VERSION "Tesla Model Y HW4 read-only perception and navigation subset"

NS_ :

BS_:

BU_: UI DAS APP

CM_ "Read-only Model Y HW4 visualization subset. Source: https://tcan.latency.is/?plat=ModelY, retrieved 2026-08-03. Counter and checksum fields are intentionally omitted.";

BO_ 568 UI_driverAssistMapData: 8 UI
 SG_ UI_mapSpeedLimitDependency : 0|3@1+ (1,0) [0|7] "" DAS
 SG_ UI_roadClass : 3|3@1+ (1,0) [0|7] "" DAS
 SG_ UI_inSuperchargerGeofence : 6|1@1+ (1,0) [0|1] "" DAS
 SG_ UI_mapSpeedUnits : 7|1@1+ (1,0) [0|1] "" DAS
 SG_ UI_mapSpeedLimit : 8|5@1+ (1,0) [0|31] "" DAS
 SG_ UI_mapSpeedLimitType : 13|3@1+ (1,0) [0|7] "" DAS
 SG_ UI_countryCode : 16|10@1+ (1,0) [0|1023] "" DAS
 SG_ UI_streetCount : 26|2@1+ (1,0) [0|3] "" DAS
 SG_ UI_gpsRoadMatch : 28|1@1+ (1,0) [0|1] "" DAS
 SG_ UI_navRouteActive : 29|1@1+ (1,0) [0|1] "" DAS
 SG_ UI_parallelAutoparkEnabled : 30|1@1+ (1,0) [0|1] "" DAS
 SG_ UI_perpendicularAutoparkEnabled : 31|1@1+ (1,0) [0|1] "" DAS
 SG_ UI_nextBranchDist : 32|5@1+ (10,0) [0|310] "m" DAS
 SG_ UI_controlledAccess : 37|1@1+ (1,0) [0|1] "" DAS
 SG_ UI_nextBranchLeftOffRamp : 38|1@1+ (1,0) [0|1] "" DAS
 SG_ UI_nextBranchRightOffRamp : 39|1@1+ (1,0) [0|1] "" DAS
 SG_ UI_rejectLeftLane : 40|1@1+ (1,0) [0|1] "" DAS
 SG_ UI_rejectRightLane : 41|1@1+ (1,0) [0|1] "" DAS
 SG_ UI_rejectHPP : 42|1@1+ (1,0) [0|1] "" DAS
 SG_ UI_rejectNav : 43|1@1+ (1,0) [0|1] "" DAS
 SG_ UI_rejectLeftFreeSpace : 44|1@1+ (1,0) [0|1] "" DAS
 SG_ UI_rejectRightFreeSpace : 45|1@1+ (1,0) [0|1] "" DAS
 SG_ UI_rejectAutosteer : 46|1@1+ (1,0) [0|1] "" DAS
 SG_ UI_rejectHandsOn : 47|1@1+ (1,0) [0|1] "" DAS
 SG_ UI_acceptBottsDots : 48|1@1+ (1,0) [0|1] "" DAS
 SG_ UI_autosteerRestricted : 49|1@1+ (1,0) [0|1] "" DAS
 SG_ UI_pmmEnabled : 50|1@1+ (1,0) [0|1] "" DAS
 SG_ UI_scaEnabled : 51|1@1+ (1,0) [0|1] "" DAS

BO_ 586 DAS_visualDebug: 8 DAS
 SG_ DAS_autosteerVehiclesUsage : 4|2@1+ (1,0) [0|3] "" UI
 SG_ DAS_autosteerHPPUsage : 6|2@1+ (1,0) [0|3] "" UI
 SG_ DAS_autosteerNavigationUsage : 8|2@1+ (1,0) [0|3] "" UI
 SG_ DAS_autosteerModelUsage : 10|2@1+ (1,0) [0|3] "" UI
 SG_ DAS_autosteerBottsDotsUsage : 12|2@1+ (1,0) [0|3] "" UI
 SG_ DAS_offsetSide : 14|2@1+ (1,0) [0|3] "" UI
 SG_ DAS_roadSurfaceType : 16|2@1+ (1,0) [0|3] "" UI
 SG_ DAS_autosteerHealthAnomalyLevel : 18|3@1+ (1,0) [0|7] "" UI
 SG_ DAS_autosteerHealthState : 21|3@1+ (1,0) [0|7] "" UI
 SG_ DAS_lastLinePreferenceReason : 24|4@1+ (1,0) [0|15] "" UI
 SG_ DAS_plannerState : 28|4@1+ (1,0) [0|15] "" UI
 SG_ DAS_lastAutosteerAbortReason : 32|6@1+ (1,0) [0|63] "" UI
 SG_ DAS_devAppInterfaceEnabled : 38|1@1+ (1,0) [0|1] "" UI
 SG_ DAS_navAvailable : 39|1@1+ (1,0) [0|1] "" UI
 SG_ DAS_navDistance : 40|8@1+ (100,0) [0|25500] "m" UI
 SG_ DAS_accSmartSpeedActive : 48|1@1+ (1,0) [0|1] "" UI
 SG_ DAS_accSmartSpeedState : 49|3@1+ (1,0) [0|7] "" UI
 SG_ DAS_ulcInProgress : 52|1@1+ (1,0) [0|1] "" UI
 SG_ DAS_trafficAwareSetSpeedInUse : 53|1@1+ (1,0) [0|1] "" UI
 SG_ DAS_isaSystemState : 54|2@1+ (1,0) [0|3] "" UI
 SG_ DAS_behaviorType : 56|2@1+ (1,0) [0|3] "" UI
 SG_ DAS_ulcType : 58|2@1+ (1,0) [0|3] "" UI
 SG_ DAS_rearVehDetectedThisCycle : 60|1@1+ (1,0) [0|1] "" UI
 SG_ DAS_rearLeftVehDetectedCurrent : 61|1@1+ (1,0) [0|1] "" UI
 SG_ DAS_rearRightVehDetectedTrip : 62|1@1+ (1,0) [0|1] "" UI
 SG_ DAS_rearLeftVehDetectedTrip : 63|1@1+ (1,0) [0|1] "" UI

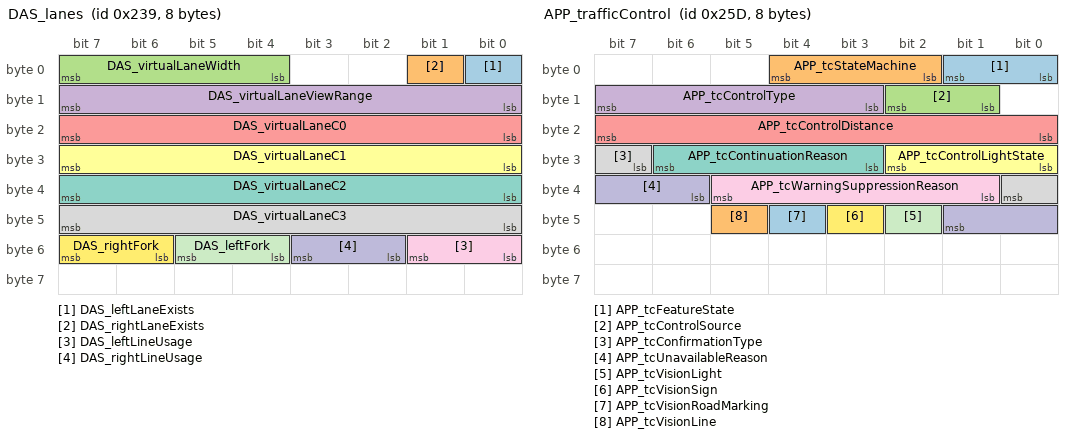
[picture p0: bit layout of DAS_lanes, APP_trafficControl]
BO_ 569 DAS_lanes: 8 DAS
 SG_ DAS_leftLaneExists : 0|1@1+ (1,0) [0|1] "" UI
 SG_ DAS_rightLaneExists : 1|1@1+ (1,0) [0|1] "" UI
 SG_ DAS_virtualLaneWidth : 4|4@1+ (0.3125,2) [2|6.6875] "m" UI
 SG_ DAS_virtualLaneViewRange : 8|8@1+ (1,0) [0|255] "m" UI
 SG_ DAS_virtualLaneC0 : 16|8@1+ (0.035,-3.5) [-3.5|5.425] "m" UI
 SG_ DAS_virtualLaneC1 : 24|8@1+ (0.0016,-0.2) [-0.2|0.208] "rad" UI
 SG_ DAS_virtualLaneC2 : 32|8@1+ (0.00002,-0.0025) [-0.0025|0.0026] "m-1" UI
 SG_ DAS_virtualLaneC3 : 40|8@1+ (0.00000024,-0.00003) [-0.00003|0.0000312] "m-2" UI
 SG_ DAS_leftLineUsage : 48|2@1+ (1,0) [0|3] "" UI
 SG_ DAS_rightLineUsage : 50|2@1+ (1,0) [0|3] "" UI
 SG_ DAS_leftFork : 52|2@1+ (1,0) [0|3] "" UI
 SG_ DAS_rightFork : 54|2@1+ (1,0) [0|3] "" UI

BO_ 605 APP_trafficControl: 8 APP
 SG_ APP_tcFeatureState : 0|2@1+ (1,0) [0|3] "" UI
 SG_ APP_tcStateMachine : 2|3@1+ (1,0) [0|7] "" UI
 SG_ APP_tcControlSource : 9|2@1+ (1,0) [0|3] "" UI
 SG_ APP_tcControlType : 11|5@1+ (1,0) [0|31] "" UI
 SG_ APP_tcControlDistance : 16|8@1+ (1,0) [0|255] "m" UI
 SG_ APP_tcControlLightState : 24|3@1+ (1,0) [0|7] "" UI
 SG_ APP_tcContinuationReason : 27|4@1+ (1,0) [0|15] "" UI
 SG_ APP_tcConfirmationType : 31|2@1+ (1,0) [0|3] "" UI
 SG_ APP_tcWarningSuppressionReason : 33|5@1+ (1,0) [0|31] "" UI
 SG_ APP_tcUnavailableReason : 38|4@1+ (1,0) [0|15] "" UI
 SG_ APP_tcVisionLight : 42|1@1+ (1,0) [0|1] "" UI
 SG_ APP_tcVisionSign : 43|1@1+ (1,0) [0|1] "" UI
 SG_ APP_tcVisionRoadMarking : 44|1@1+ (1,0) [0|1] "" UI
 SG_ APP_tcVisionLine : 45|1@1+ (1,0) [0|1] "" UI

BO_ 778 DAS_object: 8 DAS
 SG_ DAS_objectId M : 0|3@1+ (1,0) [0|7] "" UI
 SG_ DAS_leadVehType m0 : 3|3@1+ (1,0) [0|7] "" UI
 SG_ DAS_leadVehRelevantForControl m0 : 7|1@1+ (1,0) [0|1] "" UI
 SG_ DAS_leadVehDx m0 : 8|8@1+ (0.5,0) [0|127.5] "m" UI
 SG_ DAS_leadVehVxRel m0 : 16|4@1+ (4,-30) [-30|30] "" UI
 SG_ DAS_leadVehDy m0 : 20|7@1+ (0.35,-22.05) [-22.05|22.4] "m" UI
 SG_ DAS_leadVehId m0 : 27|7@1+ (1,0) [0|127] "" UI
 SG_ DAS_leadVeh2Type m0 : 34|3@1+ (1,0) [0|7] "" UI
 SG_ DAS_leadVeh2RelevantForControl m0 : 38|1@1+ (1,0) [0|1] "" UI
 SG_ DAS_leadVeh2Dx m0 : 39|8@1+ (0.5,0) [0|127.5] "m" UI
 SG_ DAS_leadVeh2VxRel m0 : 47|4@1+ (4,-30) [-30|30] "" UI
 SG_ DAS_leadVeh2Dy m0 : 51|7@1+ (0.35,-22.05) [-22.05|22.4] "m" UI
 SG_ DAS_leadVeh2Id m0 : 58|6@1+ (1,0) [0|63] "" UI
 SG_ DAS_leftVehType m1 : 3|3@1+ (1,0) [0|7] "" UI
 SG_ DAS_leftVehRelevantForControl m1 : 7|1@1+ (1,0) [0|1] "" UI
 SG_ DAS_leftVehDx m1 : 8|8@1+ (0.5,0) [0|127.5] "m" UI
 SG_ DAS_leftVehVxRel m1 : 16|4@1+ (4,-30) [-30|30] "" UI
 SG_ DAS_leftVehDy m1 : 20|7@1+ (0.35,-22.05) [-22.05|22.4] "m" UI
 SG_ DAS_leftVehId m1 : 27|7@1+ (1,0) [0|127] "" UI
 SG_ DAS_leftVeh2Type m1 : 34|3@1+ (1,0) [0|7] "" UI
 SG_ DAS_leftVeh2RelevantForControl m1 : 38|1@1+ (1,0) [0|1] "" UI
 SG_ DAS_leftVeh2Dx m1 : 39|8@1+ (0.5,0) [0|127.5] "m" UI
 SG_ DAS_leftVeh2VxRel m1 : 47|4@1+ (4,-30) [-30|30] "" UI
 SG_ DAS_leftVeh2Dy m1 : 51|7@1+ (0.35,-22.05) [-22.05|22.4] "m" UI
 SG_ DAS_leftVeh2Id m1 : 58|6@1+ (1,0) [0|63] "" UI
 SG_ DAS_rightVehType m2 : 3|3@1+ (1,0) [0|7] "" UI
 SG_ DAS_rightVehRelevantForControl m2 : 7|1@1+ (1,0) [0|1] "" UI
 SG_ DAS_rightVehDx m2 : 8|8@1+ (0.5,0) [0|127.5] "m" UI
 SG_ DAS_rightVehVxRel m2 : 16|4@1+ (4,-30) [-30|30] "" UI
 SG_ DAS_rightVehDy m2 : 20|7@1+ (0.35,-22.05) [-22.05|22.4] "m" UI
 SG_ DAS_rightVehId m2 : 27|7@1+ (1,0) [0|127] "" UI
 SG_ DAS_rightVeh2Type m2 : 34|3@1+ (1,0) [0|7] "" UI
 SG_ DAS_rightVeh2RelevantForControl m2 : 38|1@1+ (1,0) [0|1] "" UI
 SG_ DAS_rightVeh2Dx m2 : 39|8@1+ (0.5,0) [0|127.5] "m" UI
 SG_ DAS_rightVeh2VxRel m2 : 47|4@1+ (4,-30) [-30|30] "" UI
 SG_ DAS_rightVeh2Dy m2 : 51|7@1+ (0.35,-22.05) [-22.05|22.4] "m" UI
 SG_ DAS_rightVeh2Id m2 : 58|6@1+ (1,0) [0|63] "" UI
 SG_ DAS_cutinVehType m3 : 3|3@1+ (1,0) [0|7] "" UI
 SG_ DAS_cutinVehRelevantForControl m3 : 7|1@1+ (1,0) [0|1] "" UI
 SG_ DAS_cutinVehDx m3 : 8|8@1+ (0.5,0) [0|127.5] "m" UI
 SG_ DAS_cutinVehVxRel m3 : 16|4@1+ (4,-30) [-30|30] "" UI
 SG_ DAS_cutinVehDy m3 : 20|7@1+ (0.35,-22.05) [-22.05|22.4] "m" UI
 SG_ DAS_cutinVehId m3 : 27|7@1+ (1,0) [0|127] "" UI
 SG_ DAS_cutinVehHeading m3 : 56|8@1+ (0.0245437,-3.1415936) [-3.1415936|3.116] "rad" UI
 SG_ DAS_roadSignColor m4 : 3|3@1+ (1,0) [0|7] "" UI
 SG_ DAS_roadSignId m4 : 6|8@1+ (1,0) [0|255] "" UI
 SG_ DAS_roadSignStopLineDist m4 : 14|10@1+ (0.2,-20) [-20|184.6] "m" UI
 SG_ DAS_roadSignControlActive m4 : 24|1@1+ (1,0) [0|1] "" UI
 SG_ DAS_roadSignSource m4 : 25|2@1+ (1,0) [0|3] "" UI
 SG_ DAS_roadSignArrow m4 : 27|3@1+ (1,0) [0|7] "" UI
 SG_ DAS_roadSignOrientation m4 : 30|2@1+ (1,0) [0|3] "" UI
 SG_ DAS_leadVehHeading m5 : 8|8@1+ (0.0245437,-3.1415936) [-3.1415936|3.116] "rad" UI
 SG_ DAS_leadVeh2Heading m5 : 16|8@1+ (0.0245437,-3.1415936) [-3.1415936|3.116] "rad" UI
 SG_ DAS_leftVehHeading m5 : 24|8@1+ (0.0245437,-3.1415936) [-3.1415936|3.116] "rad" UI
 SG_ DAS_leftVeh2Heading m5 : 32|8@1+ (0.0245437,-3.1415936) [-3.1415936|3.116] "rad" UI
 SG_ DAS_rightVehHeading m5 : 40|8@1+ (0.0245437,-3.1415936) [-3.1415936|3.116] "rad" UI
 SG_ DAS_rightVeh2Heading m5 : 48|8@1+ (0.0245437,-3.1415936) [-3.1415936|3.116] "rad" UI

BO_ 536 UI_driverAssistRoadSign: 8 UI
 SG_ UI_roadSign M : 0|8@1+ (1,0) [0|255] "" DAS
 SG_ UI_dummyData m0 : 8|1@1+ (1,0) [0|1] "" DAS
 SG_ UI_stopSignStopLineDist m1 : 8|10@1+ (0.25,-8) [-8|247.75] "m" DAS
 SG_ UI_stopSignStopLineConf m1 : 18|7@1+ (1,0) [0|127] "" DAS
 SG_ UI_trafficLightStopLineDist m2 : 8|10@1+ (0.25,-8) [-8|247.75] "m" DAS
 SG_ UI_trafficLightStopLineConf m2 : 18|7@1+ (1,0) [0|127] "" DAS
 SG_ UI_baseMapSpeedLimitMPS m3 : 8|8@1+ (0.25,0) [0|63.75] "m/s" DAS
 SG_ UI_bottomQrtlFleetSpeedMPS m3 : 16|8@1+ (0.25,0) [0|63.75] "m/s" DAS
 SG_ UI_topQrtlFleetSpeedMPS m3 : 24|8@1+ (0.25,0) [0|63.75] "m/s" DAS
 SG_ UI_meanFleetSplineSpeedMPS m4 : 8|8@1+ (0.25,0) [0|63.75] "m/s" DAS
 SG_ UI_medianFleetSpeedMPS m4 : 16|8@1+ (0.25,0) [0|63.75] "m/s" DAS
 SG_ UI_meanFleetSplineAccelMPS2 m4 : 24|8@1+ (0.05,-6.35) [-6.35|6.4] "m/s2" DAS
 SG_ UI_rampType m4 : 32|3@1+ (1,0) [0|7] "" DAS
 SG_ UI_valhallaRamp m4 : 35|2@1+ (1,0) [0|3] "" DAS
 SG_ UI_overrideACMFleetSpeed m4 : 38|1@1+ (1,0) [0|1] "" DAS
 SG_ UI_currSplineIdFull m5 : 8|32@1+ (1,0) [0|4294967295] "" DAS
 SG_ UI_splineLocConfidence : 40|7@1+ (1,0) [0|127] "" DAS
 SG_ UI_splineID : 48|4@1+ (1,0) [0|15] "" DAS
 SG_ UI_roadSignCounter : 52|4@1+ (1,0) [0|15] "" DAS
 SG_ UI_roadSignChecksum : 56|8@1+ (1,0) [0|255] "" DAS

BO_ 665 DAS_integratedSafetyFront: 8 DAS
 SG_ DAS_safetyFrontChecksum : 0|8@1+ (1,0) [0|255] "" DAS
 SG_ DAS_safetyFrontCounter : 8|4@1+ (1,0) [0|15] "" DAS
 SG_ DAS_timeToImpactFront : 12|9@1+ (1,0) [0|511] "s" DAS
 SG_ DAS_timeToImpactFrontQF : 21|1@1+ (1,0) [0|1] "" DAS
 SG_ DAS_predictedImpactVelFront : 22|7@1+ (0.5,0) [0|63.5] "m/s" DAS
 SG_ DAS_predictedImpactVelFrontQF : 29|1@1+ (1,0) [0|1] "" DAS
 SG_ DAS_relativeVelocityFront : 30|6@1+ (1,-32) [-32|31] "m/s" DAS
 SG_ DAS_relativeVelocityFrontQF : 36|1@1+ (1,0) [0|1] "" DAS
 SG_ DAS_targetDistanceFront : 37|7@1+ (0.1,0) [0|12.7] "m" DAS
 SG_ DAS_targetDistanceFrontQF : 44|1@1+ (1,0) [0|1] "" DAS
 SG_ DAS_relativeAccelerationFront : 45|8@1+ (0.1,-12.8) [-12.8|12.7] "m/s2" DAS
 SG_ DAS_relativeAccelerationFrontQF : 53|1@1+ (1,0) [0|1] "" DAS
 SG_ DAS_imminentCollisionFront : 54|1@1+ (1,0) [0|1] "" DAS
 SG_ DAS_imminentCollisionFrontQF : 55|1@1+ (1,0) [0|1] "" DAS
 SG_ DAS_predictedImpactOvrlapFront : 56|3@1+ (12.5,0) [0|87.5] "%" DAS
 SG_ DAS_predictedImpactOvrlapFrontQF : 59|1@1+ (1,0) [0|1] "" DAS
 SG_ DAS_idfEnableFlag : 60|1@1+ (1,0) [0|1] "" DAS

BO_ 921 DAS_statusCH: 8 DAS
 SG_ DAS_autopilotState : 0|4@1+ (1,0) [0|15] "" DAS
 SG_ DAS_blindSpotRearLeft : 4|2@1+ (1,0) [0|3] "" DAS
 SG_ DAS_blindSpotRearRight : 6|2@1+ (1,0) [0|3] "" DAS
 SG_ DAS_fusedSpeedLimit : 8|5@1+ (5,0) [0|155] "kph" DAS
 SG_ DAS_suppressSpeedWarning : 13|1@1+ (1,0) [0|1] "" DAS
 SG_ DAS_summonObstacle : 14|1@1+ (1,0) [0|1] "" DAS
 SG_ DAS_summonClearedGate : 15|1@1+ (1,0) [0|1] "" DAS
 SG_ DAS_visionOnlySpeedLimit : 16|5@1+ (5,0) [0|155] "kph" DAS
 SG_ DAS_heaterState : 21|1@1+ (1,0) [0|1] "" DAS
 SG_ DAS_forwardCollisionWarning : 22|2@1+ (1,0) [0|3] "" DAS
 SG_ DAS_autoparkReady : 24|1@1+ (1,0) [0|1] "" DAS
 SG_ DAS_autoParked : 25|1@1+ (1,0) [0|1] "" DAS
 SG_ DAS_autoparkActive : 26|1@1+ (1,0) [0|1] "" DAS
 SG_ DAS_summonFwdLeashReached : 27|1@1+ (1,0) [0|1] "" DAS
 SG_ DAS_summonRvsLeashReached : 28|1@1+ (1,0) [0|1] "" DAS
 SG_ DAS_lssState : 29|3@1+ (1,0) [0|7] "" DAS
 SG_ DAS_sideCollisionAvoid : 32|2@1+ (1,0) [0|3] "" DAS
 SG_ DAS_sideCollisionWarning : 34|2@1+ (1,0) [0|3] "" DAS
 SG_ DAS_sideCollisionInhibit : 36|1@1+ (1,0) [0|1] "" DAS
 SG_ DAS_laneDepartureWarning : 37|3@1+ (1,0) [0|7] "" DAS
 SG_ DAS_fleetSpeedState : 40|2@1+ (1,0) [0|3] "" DAS
 SG_ DAS_autopilotHandsOnState : 42|4@1+ (1,0) [0|15] "" DAS
 SG_ DAS_autoLaneChangeState : 46|5@1+ (1,0) [0|31] "" DAS
 SG_ DAS_summonAvailable : 51|1@1+ (1,0) [0|1] "" DAS
 SG_ DAS_statusCounter : 52|4@1+ (1,0) [0|15] "" DAS
 SG_ DAS_statusChecksum : 56|8@1+ (1,0) [0|255] "" DAS

BO_ 923 DAS_status: 8 DAS
 SG_ DAS_autopilotState : 0|4@1+ (1,0) [0|15] "" DAS
 SG_ DAS_blindSpotRearLeft : 4|2@1+ (1,0) [0|3] "" DAS
 SG_ DAS_blindSpotRearRight : 6|2@1+ (1,0) [0|3] "" DAS
 SG_ DAS_fusedSpeedLimit : 8|5@1+ (5,0) [0|155] "kph" DAS
 SG_ DAS_suppressSpeedWarning : 13|1@1+ (1,0) [0|1] "" DAS
 SG_ DAS_summonObstacle : 14|1@1+ (1,0) [0|1] "" DAS
 SG_ DAS_summonClearedGate : 15|1@1+ (1,0) [0|1] "" DAS
 SG_ DAS_visionOnlySpeedLimit : 16|5@1+ (5,0) [0|155] "kph" DAS
 SG_ DAS_heaterState : 21|1@1+ (1,0) [0|1] "" DAS
 SG_ DAS_forwardCollisionWarning : 22|2@1+ (1,0) [0|3] "" DAS
 SG_ DAS_autoparkReady : 24|1@1+ (1,0) [0|1] "" DAS
 SG_ DAS_autoParked : 25|1@1+ (1,0) [0|1] "" DAS
 SG_ DAS_autoparkActive : 26|1@1+ (1,0) [0|1] "" DAS
 SG_ DAS_summonFwdLeashReached : 27|1@1+ (1,0) [0|1] "" DAS
 SG_ DAS_summonRvsLeashReached : 28|1@1+ (1,0) [0|1] "" DAS
 SG_ DAS_lssState : 29|3@1+ (1,0) [0|7] "" DAS
 SG_ DAS_sideCollisionAvoid : 32|2@1+ (1,0) [0|3] "" DAS
 SG_ DAS_sideCollisionWarning : 34|2@1+ (1,0) [0|3] "" DAS
 SG_ DAS_sideCollisionInhibit : 36|1@1+ (1,0) [0|1] "" DAS
 SG_ DAS_laneDepartureWarning : 37|3@1+ (1,0) [0|7] "" DAS
 SG_ DAS_fleetSpeedState : 40|2@1+ (1,0) [0|3] "" DAS
 SG_ DAS_autopilotHandsOnState : 42|4@1+ (1,0) [0|15] "" DAS
 SG_ DAS_autoLaneChangeState : 46|5@1+ (1,0) [0|31] "" DAS
 SG_ DAS_summonAvailable : 51|1@1+ (1,0) [0|1] "" DAS
 SG_ DAS_statusCounter : 52|4@1+ (1,0) [0|15] "" DAS
 SG_ DAS_statusChecksum : 56|8@1+ (1,0) [0|255] "" DAS

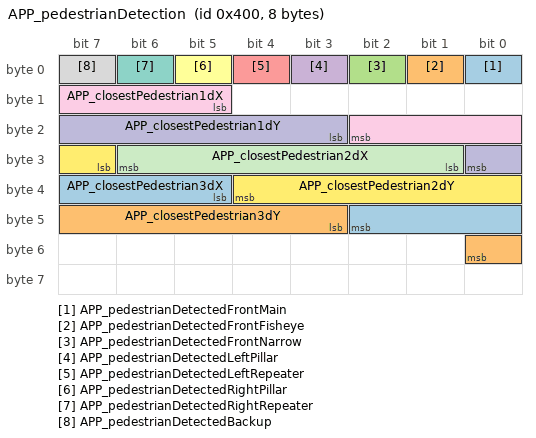
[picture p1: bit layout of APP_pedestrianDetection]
BO_ 1024 APP_pedestrianDetection: 8 APP
 SG_ APP_pedestrianDetectedFrontMain : 0|1@1+ (1,0) [0|1] "" DAS
 SG_ APP_pedestrianDetectedFrontFisheye : 1|1@1+ (1,0) [0|1] "" DAS
 SG_ APP_pedestrianDetectedFrontNarrow : 2|1@1+ (1,0) [0|1] "" DAS
 SG_ APP_pedestrianDetectedLeftPillar : 3|1@1+ (1,0) [0|1] "" DAS
 SG_ APP_pedestrianDetectedLeftRepeater : 4|1@1+ (1,0) [0|1] "" DAS
 SG_ APP_pedestrianDetectedRightPillar : 5|1@1+ (1,0) [0|1] "" DAS
 SG_ APP_pedestrianDetectedRightRepeater : 6|1@1+ (1,0) [0|1] "" DAS
 SG_ APP_pedestrianDetectedBackup : 7|1@1+ (1,0) [0|1] "" DAS
 SG_ APP_closestPedestrian1dX : 13|6@1- (0.4,0) [-12.8|12.4] "m" DAS
 SG_ APP_closestPedestrian1dY : 19|6@1- (0.4,0) [-12.8|12.4] "m" DAS
 SG_ APP_closestPedestrian2dX : 25|6@1- (0.4,0) [-12.8|12.4] "m" DAS
 SG_ APP_closestPedestrian2dY : 31|6@1- (0.4,0) [-12.8|12.4] "m" DAS
 SG_ APP_closestPedestrian3dX : 37|6@1- (0.4,0) [-12.8|12.4] "m" DAS
 SG_ APP_closestPedestrian3dY : 43|6@1- (0.4,0) [-12.8|12.4] "m" DAS

VAL_ 568 UI_mapSpeedUnits 0 "MPH" 1 "KPH" ;
VAL_ 568 UI_roadClass 0 "UNKNOWN_INVALID_SNA" 1 "CLASS_1_MAJOR" 2 "CLASS_2" 3 "CLASS_3" 4 "CLASS_4" 5 "CLASS_5" 6 "CLASS_6_MINOR" ;
VAL_ 568 UI_mapSpeedLimitType 1 "REGULAR" 2 "ADVISORY" 3 "DEPENDENT" 4 "BUMPS" 7 "UNKNOWN_SNA" ;
VAL_ 586 DAS_autosteerNavigationUsage 0 "REJECTED_UNAVAILABLE" 1 "AVAILABLE" 2 "FUSED" 3 "BLACKLISTED" ;
VAL_ 586 DAS_plannerState 0 "DISABLED" 1 "VL" 2 "FOLLOW" 3 "LANECHANGE_REQUESTED" 4 "LANECHANGE_IN_PROGRESS" 5 "LANECHANGE_WAIT_FOR_SIDE_OBSTACLE" 6 "LANECHANGE_WAIT_FOR_FWD_OBSTACLE" 7 "LANECHANGE_ABORT" ;
VAL_ 586 DAS_behaviorType 0 "INVALID" 1 "IN_LANE" 2 "LANE_CHANGE_LEFT" 3 "LANE_CHANGE_RIGHT" ;
VAL_ 586 DAS_roadSurfaceType 0 "SNA" 1 "NORMAL" 2 "ENHANCED" ;
VAL_ 586 DAS_autosteerHealthState 0 "UNAVAILABLE" 1 "NOMINAL" 2 "DEGRADED" 3 "SEVERELY_DEGRADED" 4 "ABORTING" 5 "FAULT" ;
VAL_ 569 DAS_leftLineUsage 0 "REJECTED_UNAVAILABLE" 1 "AVAILABLE" 2 "FUSED" 3 "BLACKLISTED" ;
VAL_ 569 DAS_rightLineUsage 0 "REJECTED_UNAVAILABLE" 1 "AVAILABLE" 2 "FUSED" 3 "BLACKLISTED" ;
VAL_ 569 DAS_leftFork 0 "NONE" 1 "AVAILABLE" 2 "SELECTED" 3 "UNAVAILABLE" ;
VAL_ 569 DAS_rightFork 0 "NONE" 1 "AVAILABLE" 2 "SELECTED" 3 "UNAVAILABLE" ;
VAL_ 605 APP_tcFeatureState 0 "DISABLED" 1 "UNAVAILABLE" 2 "AVAILABLE" 3 "ACTIVE" ;
VAL_ 605 APP_tcStateMachine 0 "DISABLED" 1 "STANDBY" 2 "AWARE" 3 "WARNING" 4 "STOPPING" 5 "STOPPED" 6 "CONTINUING" ;
VAL_ 605 APP_tcControlSource 0 "NONE" 1 "MAP" 2 "VISION" 3 "MAP_AND_VISION" ;
VAL_ 605 APP_tcControlType 0 "INVALID" 1 "UNKNOWN" 2 "STOP_SIGN" 3 "TRAFFIC_LIGHT" 4 "YIELD" 5 "CROSSWALK" 6 "KEEP_CLEAR_ENTER" 7 "KEEP_CLEAR_EXIT" 8 "SUICIDE_LEFT" 9 "PEDESTRIAN_CROSSING" 10 "RAMP_METER" 11 "SPEED_BUMP" 12 "SPEED_HUMP" 13 "TRAFFIC_RULE" 14 "ALL_WAY_STOP_SIGN" 15 "BIKE_MERGE_FROM_LEFT" 16 "BIKE_MERGE_FROM_RIGHT" 17 "NO_STOP" 18 "T_IMPLICIT" 19 "T_IMPLICIT_BY_NAME" 20 "T_IMPLICIT_BY_GEOM" 21 "BEV_JUNCTION" 22 "T_ARM" ;
VAL_ 605 APP_tcControlLightState 0 "NONE" 1 "RED" 2 "GREEN" 3 "YELLOW" 4 "OFF" 5 "WHITE" 6 "OTHER" ;
VAL_ 778 DAS_objectId 0 "LEAD_VEHICLES" 1 "LEFT_VEHICLES" 2 "RIGHT_VEHICLES" 3 "CUTIN_VEHICLE" 4 "ROAD_SIGN" 5 "VEHICLE_HEADINGS" ;
VAL_ 778 DAS_leadVehType 0 "UNKNOWN" 1 "TRUCK" 2 "CAR" 3 "MOTORCYCLE" 4 "BICYCLE" 5 "PEDESTRIAN" 6 "IPSO" ;
VAL_ 778 DAS_leftVehType 0 "UNKNOWN" 1 "TRUCK" 2 "CAR" 3 "MOTORCYCLE" 4 "BICYCLE" 5 "PEDESTRIAN" ;
VAL_ 778 DAS_rightVehType 0 "UNKNOWN" 1 "TRUCK" 2 "CAR" 3 "MOTORCYCLE" 4 "BICYCLE" 5 "PEDESTRIAN" ;
VAL_ 778 DAS_cutinVehType 0 "UNKNOWN" 1 "TRUCK" 2 "CAR" 3 "MOTORCYCLE" 4 "BICYCLE" 5 "PEDESTRIAN" ;
VAL_ 778 DAS_roadSignColor 0 "NONE" 1 "RED" 2 "YELLOW" 3 "GREEN" 4 "RED_YELLOW" ;
VAL_ 778 DAS_roadSignId 0 "STOP_SIGN" 1 "TRAFFIC_LIGHT" 255 "SNA" ;
VAL_ 778 DAS_roadSignSource 0 "NONE" 1 "NAV" 2 "VISION" ;
VAL_ 778 DAS_roadSignArrow 0 "CIRCLE" 1 "LEFT" 2 "RIGHT" 3 "STRAIGHT" 4 "UNKNOWN" ;
VAL_ 778 DAS_roadSignOrientation 0 "UNKNOWN" 1 "VERTICAL_3_LIGHT" 2 "HORIZONTAL_3_LIGHT" ;
